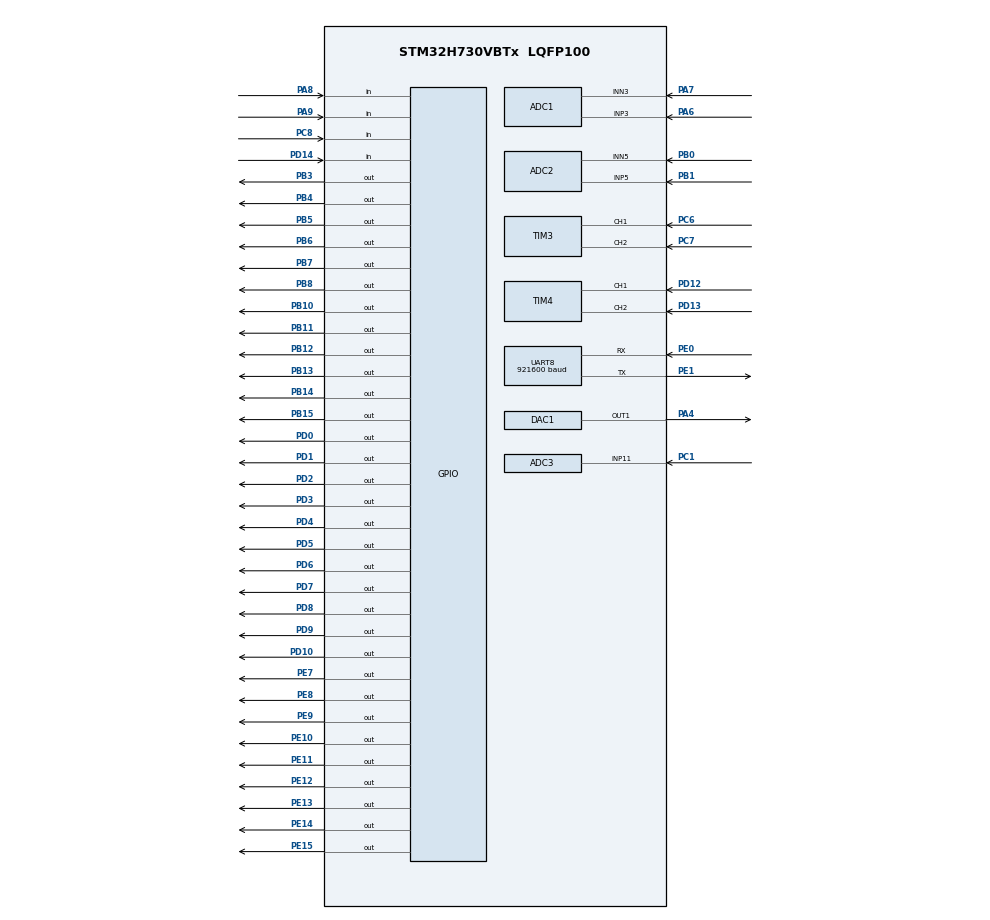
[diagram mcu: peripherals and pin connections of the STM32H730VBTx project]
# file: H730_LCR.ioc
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ADC1.Channel-1\#ChannelRegularConversion=ADC_CHANNEL_3
ADC1.ClockPrescaler=ADC_CLOCK_ASYNC_DIV1
ADC1.ClockPrescalerADC3=ADC_CLOCK_ASYNC_DIV16
ADC1.ContinuousConvMode=ENABLE
ADC1.ConversionDataManagement=ADC_CONVERSIONDATA_DR
ADC1.ExternalTrigConv=ADC_SOFTWARE_START
ADC1.Mode=ADC_DUALMODE_REGSIMULT
ADC1.NbrOfConversionFlag=1
ADC1.OffsetNumber-1\#ChannelRegularConversion=ADC_OFFSET_NONE
ADC1.OffsetSignedSaturation-1\#ChannelRegularConversion=DISABLE
ADC1.Overrun=ADC_OVR_DATA_OVERWRITTEN
ADC1.Rank-1\#ChannelRegularConversion=1
ADC1.SamplingTime-1\#ChannelRegularConversion=ADC_SAMPLETIME_8CYCLES_5
ADC1.SingleDiff-1\#ChannelRegularConversion=ADC_DIFFERENTIAL_ENDED
ADC1.master=1
ADC2.Channel-1\#ChannelRegularConversion=ADC_CHANNEL_5
ADC2.ClockPrescalerADC3=ADC_CLOCK_ASYNC_DIV16
ADC2.ContinuousConvMode=ENABLE
ADC2.ConversionDataManagement=ADC_CONVERSIONDATA_DR
ADC2.Mode=ADC_DUALMODE_REGSIMULT
ADC2.NbrOfConversionFlag=1
ADC2.OffsetNumber-1\#ChannelRegularConversion=ADC_OFFSET_NONE
ADC2.OffsetSignedSaturation-1\#ChannelRegularConversion=DISABLE
ADC2.Overrun=ADC_OVR_DATA_OVERWRITTEN
ADC2.Rank-1\#ChannelRegularConversion=1
ADC2.SamplingTime-1\#ChannelRegularConversion=ADC_SAMPLETIME_8CYCLES_5
ADC2.SingleDiff-1\#ChannelRegularConversion=ADC_DIFFERENTIAL_ENDED
ADC3.Channel-5\#ChannelRegularConversion=ADC_CHANNEL_11
ADC3.ClockPrescaler=ADC_CLOCK_ASYNC_DIV1
ADC3.ClockPrescalerADC3=ADC_CLOCK_ASYNC_DIV16
ADC3.Mode=ADC_DUALMODE_REGSIMULT
ADC3.NbrOfConversionFlag=1
ADC3.OffsetNumber-5\#ChannelRegularConversion=ADC_OFFSET_NONE
ADC3.OffsetSign-5\#ChannelRegularConversion=ADC3_OFFSET_SIGN_NEGATIVE
ADC3.OversamplingMode=ENABLE
ADC3.Rank-5\#ChannelRegularConversion=1
ADC3.Ratio=ADC3_OVERSAMPLING_RATIO_4
ADC3.SamplingTime-5\#ChannelRegularConversion=ADC3_SAMPLETIME_12CYCLES_5
CORTEX_M7.AccessPermission-Cortex_Memory_Protection_Unit_Region0_Settings=MPU_REGION_FULL_ACCESS
CORTEX_M7.BaseAddress-Cortex_Memory_Protection_Unit_Region0_Settings=0x24000000
CORTEX_M7.CPU_DCache=Enabled
CORTEX_M7.CPU_ICache=Enabled
CORTEX_M7.Enable-Cortex_Memory_Protection_Unit_Region0_Settings=MPU_REGION_ENABLE
CORTEX_M7.Enable-Cortex_Memory_Protection_Unit_Region1_Settings=__NULL
CORTEX_M7.IsShareable-Cortex_Memory_Protection_Unit_Region0_Settings=MPU_ACCESS_SHAREABLE
CORTEX_M7.MPU_Control=MPU_HFNMI_PRIVDEF
CORTEX_M7.Size-Cortex_Memory_Protection_Unit_Region0_Settings=MPU_REGION_SIZE_128KB
DAC1.DAC1_OutputBuffer-DAC_OUT1=DAC_OUTPUTBUFFER_DISABLE
DAC1.DAC_Channel-DAC_OUT1=DAC_CHANNEL_1
DAC1.DAC_Trigger-DAC_OUT1=DAC_TRIGGER_T7_TRGO
Dma.DAC1_CH1.0.Direction=DMA_MEMORY_TO_PERIPH
Dma.DAC1_CH1.0.EventEnable=DISABLE
Dma.DAC1_CH1.0.FIFOMode=DMA_FIFOMODE_DISABLE
Dma.DAC1_CH1.0.Instance=DMA1_Stream2
Dma.DAC1_CH1.0.MemDataAlignment=DMA_MDATAALIGN_HALFWORD
Dma.DAC1_CH1.0.MemInc=DMA_MINC_ENABLE
Dma.DAC1_CH1.0.Mode=DMA_CIRCULAR
Dma.DAC1_CH1.0.PeriphDataAlignment=DMA_PDATAALIGN_HALFWORD
Dma.DAC1_CH1.0.PeriphInc=DMA_PINC_DISABLE
Dma.DAC1_CH1.0.Polarity=HAL_DMAMUX_REQ_GEN_RISING
Dma.DAC1_CH1.0.Priority=DMA_PRIORITY_VERY_HIGH
Dma.DAC1_CH1.0.RequestNumber=1
Dma.DAC1_CH1.0.SignalID=NONE
Dma.DAC1_CH1.0.SyncEnable=DISABLE
Dma.DAC1_CH1.0.SyncPolarity=HAL_DMAMUX_SYNC_NO_EVENT
Dma.DAC1_CH1.0.SyncRequestNumber=1
Dma.DAC1_CH1.0.SyncSignalID=NONE
Dma.Request0=DAC1_CH1
Mcu.Family=STM32H7
Mcu.Name=STM32H730VBTx
Mcu.Package=LQFP100
NVIC.DMA1_Stream2_IRQn=true\:0\:0\:false\:false\:true\:false\:true\:true
NVIC.PriorityGroup=NVIC_PRIORITYGROUP_3
PA13(JTMS/SWDIO).Mode=Serial_Wire
PA13(JTMS/SWDIO).Signal=DEBUG_JTMS-SWDIO
PA14(JTCK/SWCLK).Mode=Serial_Wire
PA14(JTCK/SWCLK).Signal=DEBUG_JTCK-SWCLK
PA4.Signal=COMP_DAC11_group
PA6.Signal=ADCx_INP3
PA7.Signal=ADCx_INN3
PA8.GPIO_PuPd=GPIO_PULLUP
PA8.Signal=GPIO_Input
PA9.GPIO_PuPd=GPIO_PULLUP
PA9.Signal=GPIO_Input
PB0.Signal=ADCx_INN5
PB1.Signal=ADCx_INP5
PB10.Signal=GPIO_Output
PB11.Signal=GPIO_Output
PB12.Signal=GPIO_Output
PB13.Signal=GPIO_Output
PB14.Signal=GPIO_Output
PB15.Signal=GPIO_Output
PB3(JTDO/TRACESWO).Signal=GPIO_Output
PB4(NJTRST).Signal=GPIO_Output
PB5.Signal=GPIO_Output
PB6.Signal=GPIO_Output
PB7.Signal=GPIO_Output
PB8.Signal=GPIO_Output
PC1.Signal=ADCx_INP11
PC6.GPIO_PuPd=GPIO_NOPULL
PC6.Signal=S_TIM3_CH1
PC7.GPIO_PuPd=GPIO_NOPULL
PC7.Signal=S_TIM3_CH2
PC8.GPIO_PuPd=GPIO_PULLUP
PC8.Signal=GPIO_Input
PD0.Signal=GPIO_Output
PD1.Signal=GPIO_Output
PD10.Signal=GPIO_Output
PD12.Signal=S_TIM4_CH1
PD13.Signal=S_TIM4_CH2
PD14.GPIO_PuPd=GPIO_PULLUP
PD14.Signal=GPIO_Input
PD2.Signal=GPIO_Output
PD3.Signal=GPIO_Output
PD4.Signal=GPIO_Output
PD5.Signal=GPIO_Output
PD6.Signal=GPIO_Output
PD7.Signal=GPIO_Output
PD8.Signal=GPIO_Output
PD9.Signal=GPIO_Output
PE0.Mode=Asynchronous
PE0.Signal=UART8_RX
PE1.Mode=Asynchronous
PE1.Signal=UART8_TX
PE10.Signal=GPIO_Output
PE11.Signal=GPIO_Output
PE12.Signal=GPIO_Output
PE13.Signal=GPIO_Output
PE14.Signal=GPIO_Output
PE15.Signal=GPIO_Output
PE7.Signal=GPIO_Output
PE8.Signal=GPIO_Output
PE9.Signal=GPIO_Output
PH0-OSC_IN.Mode=HSE-External-Oscillator
PH0-OSC_IN.Signal=RCC_OSC_IN
PH1-OSC_OUT.Mode=HSE-External-Oscillator
PH1-OSC_OUT.Signal=RCC_OSC_OUT
ProjectManager.HeapSize=0x200
ProjectManager.StackSize=0x400
ProjectManager.TargetToolchain=Makefile
RCC.ADCFreq_Value=53040000
RCC.APB1Freq_Value=60000000
RCC.APB2Freq_Value=60000000
RCC.APB3Freq_Value=60000000
RCC.APB4Freq_Value=60000000
RCC.CortexFreq_Value=120000000
RCC.D1PPRE=RCC_APB3_DIV2
RCC.D2PPRE1=RCC_APB1_DIV2
RCC.D2PPRE2=RCC_APB2_DIV2
RCC.D3PPRE=RCC_APB4_DIV2
RCC.DIVM1=2
RCC.DIVM2=10
RCC.DIVM3=1
RCC.DIVN1=20
RCC.DIVN2=221
RCC.DIVN3=20
RCC.DIVP2=10
RCC.DIVQ1=20
RCC.DIVQ3=6
RCC.DIVR3=1
RCC.EnbaleCSS=false
RCC.HCLKFreq_Value=120000000
RCC.HSE_VALUE=24000000
RCC.HSIDiv=RCC_PLLSAIDIVR_2
RCC.PLL2_VCI_Range-AdvancedSettings=RCC_PLL2VCIRANGE_1
RCC.PLL2_VCO_SEL-AdvancedSettings=RCC_PLL2VCOMEDIUM
RCC.PLLSourceVirtual=RCC_PLLSOURCE_HSE
RCC.PWR_Regulator_Voltage_Scale=PWR_REGULATOR_VOLTAGE_SCALE2
RCC.RCC_MCO1Source=RCC_MCO1SOURCE_HSE
RCC.RNGCLockSelection=RCC_RNGCLKSOURCE_PLL
RCC.SYSCLKFreq_VALUE=120000000
RCC.SYSCLKSource=RCC_SYSCLKSOURCE_PLLCLK
RCC.USBCLockSelection=RCC_USBCLKSOURCE_PLL3
RCC.USBFreq_Value=80000000
SH.ADCx_INN3.0=ADC1_INN3,IN3-Differential
SH.ADCx_INN5.0=ADC2_INN5,IN5-Differential
SH.ADCx_INP11.0=ADC3_INP11,IN11-Single-Ended
SH.ADCx_INP3.0=ADC1_INP3,IN3-Differential
SH.ADCx_INP5.0=ADC2_INP5,IN5-Differential
SH.COMP_DAC11_group.0=DAC1_OUT1,DAC_OUT1
SH.S_TIM3_CH1.0=TIM3_CH1,Encoder_Interface
SH.S_TIM3_CH2.0=TIM3_CH2,Encoder_Interface
SH.S_TIM4_CH1.0=TIM4_CH1,Encoder_Interface
SH.S_TIM4_CH2.0=TIM4_CH2,Encoder_Interface
TIM3.CounterMode=TIM_COUNTERMODE_UP
TIM3.EncoderMode=TIM_ENCODERMODE_TI12
TIM3.IC1Polarity=TIM_ICPOLARITY_FALLING
TIM3.IC2Polarity=TIM_ICPOLARITY_RISING
TIM4.CounterMode=TIM_COUNTERMODE_UP
TIM4.EncoderMode=TIM_ENCODERMODE_TI12
TIM4.IC1Polarity=TIM_ICPOLARITY_FALLING
TIM4.IC2Polarity=TIM_ICPOLARITY_RISING
TIM7.Period=65535
TIM7.TIM_MasterOutputTrigger=TIM_TRGO_UPDATE
UART8.BaudRate=921600
VP_MEMORYMAP_VS_MEMORYMAP.Mode=CurAppReg
VP_RNG_VS_RNG.Mode=RNG_Activate
VP_TIM23_VS_ClockSourceINT.Mode=Internal
VP_TIM7_VS_ClockSourceINT.Mode=Enable_Timer
board=custom

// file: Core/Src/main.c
/* USER CODE BEGIN Header */
/**
 ******************************************************************************
 * @file           : main.c
 * @brief          : Main program body
 ******************************************************************************
 * @attention
 *
 * Copyright (c) 2024 STMicroelectronics.
 * All rights reserved.
 *
 * This software is licensed under terms that can be found in the LICENSE file
 * in the root directory of this software component.
 * If no LICENSE file comes with this software, it is provided AS-IS.
 *
 ******************************************************************************
 */
/* USER CODE END Header */
#include "main.h"
#include "adc.h"
#include "dac.h"
#include "dma.h"
#include "rng.h"
#include "tim.h"
#include "usart.h"
#include "gpio.h"

/* USER CODE BEGIN Includes */
#include "main_cycle.hpp"
/* USER CODE END Includes */

void SystemClock_Config(void);
void PeriphCommonClock_Config(void);
static void MPU_Config(void);

int main(void)
{

    /* MPU Configuration--------------------------------------------------------*/
    MPU_Config();

    /* Enable the CPU Cache */

    /* Enable I-Cache---------------------------------------------------------*/
    SCB_EnableICache();

    /* Enable D-Cache---------------------------------------------------------*/
    SCB_EnableDCache();

    /* MCU Configuration--------------------------------------------------------*/

    /* Reset of all peripherals, Initializes the Flash interface and the Systick. */
    HAL_Init();

    /* USER CODE BEGIN Init */
    // Reset analog peripherals
    __HAL_RCC_ADC12_FORCE_RESET();
    __HAL_RCC_ADC12_RELEASE_RESET();
    __HAL_RCC_DAC12_FORCE_RESET();
    __HAL_RCC_DAC12_RELEASE_RESET();
    /* USER CODE END Init */

    /* Configure the system clock */
    SystemClock_Config();

    /* Configure the peripherals common clocks */
    PeriphCommonClock_Config();

    /* Initialize all configured peripherals */
    MX_GPIO_Init();
    MX_DMA_Init();
    MX_ADC2_Init();
    MX_DAC1_Init();
    MX_ADC3_Init();
    MX_TIM3_Init();
    MX_TIM4_Init();
    MX_ADC1_Init();
    MX_UART8_Init();
    MX_TIM7_Init();
    MX_RNG_Init();
    MX_TIM23_Init();

    /* Infinite loop */
    /* USER CODE BEGIN WHILE */
    main_loop();
    while (1) {
        /* USER CODE END WHILE */

    }
}

void SystemClock_Config(void)
{
    RCC_OscInitTypeDef RCC_OscInitStruct = {0};
    RCC_ClkInitTypeDef RCC_ClkInitStruct = {0};

    /** Supply configuration update enable
     */
    HAL_PWREx_ConfigSupply(PWR_LDO_SUPPLY);

    /** Configure the main internal regulator output voltage
     */
    __HAL_PWR_VOLTAGESCALING_CONFIG(PWR_REGULATOR_VOLTAGE_SCALE2);

    while (!__HAL_PWR_GET_FLAG(PWR_FLAG_VOSRDY)) {
    }

    /** Initializes the RCC Oscillators according to the specified parameters
     * in the RCC_OscInitTypeDef structure.
     */
    RCC_OscInitStruct.OscillatorType = RCC_OSCILLATORTYPE_HSE;
    RCC_OscInitStruct.HSEState = RCC_HSE_ON;
    RCC_OscInitStruct.PLL.PLLState = RCC_PLL_ON;
    RCC_OscInitStruct.PLL.PLLSource = RCC_PLLSOURCE_HSE;
    RCC_OscInitStruct.PLL.PLLM = 2;
    RCC_OscInitStruct.PLL.PLLN = 20;
    RCC_OscInitStruct.PLL.PLLP = 2;
    RCC_OscInitStruct.PLL.PLLQ = 20;
    RCC_OscInitStruct.PLL.PLLR = 2;
    RCC_OscInitStruct.PLL.PLLRGE = RCC_PLL1VCIRANGE_3;
    RCC_OscInitStruct.PLL.PLLVCOSEL = RCC_PLL1VCOWIDE;
    RCC_OscInitStruct.PLL.PLLFRACN = 0;
    if (HAL_RCC_OscConfig(&RCC_OscInitStruct) != HAL_OK) {
        Error_Handler();
    }

    /** Initializes the CPU, AHB and APB buses clocks
     */
    RCC_ClkInitStruct.ClockType = RCC_CLOCKTYPE_HCLK | RCC_CLOCKTYPE_SYSCLK
                                  | RCC_CLOCKTYPE_PCLK1 | RCC_CLOCKTYPE_PCLK2
                                  | RCC_CLOCKTYPE_D3PCLK1 | RCC_CLOCKTYPE_D1PCLK1;
    RCC_ClkInitStruct.SYSCLKSource = RCC_SYSCLKSOURCE_PLLCLK;
    RCC_ClkInitStruct.SYSCLKDivider = RCC_SYSCLK_DIV1;
    RCC_ClkInitStruct.AHBCLKDivider = RCC_HCLK_DIV1;
    RCC_ClkInitStruct.APB3CLKDivider = RCC_APB3_DIV2;
    RCC_ClkInitStruct.APB1CLKDivider = RCC_APB1_DIV2;
    RCC_ClkInitStruct.APB2CLKDivider = RCC_APB2_DIV2;
    RCC_ClkInitStruct.APB4CLKDivider = RCC_APB4_DIV2;

    if (HAL_RCC_ClockConfig(&RCC_ClkInitStruct, FLASH_LATENCY_2) != HAL_OK) {
        Error_Handler();
    }
}

void PeriphCommonClock_Config(void)
{
    RCC_PeriphCLKInitTypeDef PeriphClkInitStruct = {0};

    /** Initializes the peripherals clock
     */
    PeriphClkInitStruct.PeriphClockSelection = RCC_PERIPHCLK_ADC;
    PeriphClkInitStruct.PLL2.PLL2M = 10;
    PeriphClkInitStruct.PLL2.PLL2N = 221;
    PeriphClkInitStruct.PLL2.PLL2P = 10;
    PeriphClkInitStruct.PLL2.PLL2Q = 2;
    PeriphClkInitStruct.PLL2.PLL2R = 2;
    PeriphClkInitStruct.PLL2.PLL2RGE = RCC_PLL2VCIRANGE_1;
    PeriphClkInitStruct.PLL2.PLL2VCOSEL = RCC_PLL2VCOWIDE;
    PeriphClkInitStruct.PLL2.PLL2FRACN = 0;
    PeriphClkInitStruct.AdcClockSelection = RCC_ADCCLKSOURCE_PLL2;
    if (HAL_RCCEx_PeriphCLKConfig(&PeriphClkInitStruct) != HAL_OK) {
        Error_Handler();
    }
}

/* MPU Configuration */

void MPU_Config(void)
{
    MPU_Region_InitTypeDef MPU_InitStruct = {0};

    /* Disables the MPU */
    HAL_MPU_Disable();

    /** Initializes and configures the Region and the memory to be protected
     */
    MPU_InitStruct.Enable = MPU_REGION_ENABLE;
    MPU_InitStruct.Number = MPU_REGION_NUMBER0;
    MPU_InitStruct.BaseAddress = 0x24000000;
    MPU_InitStruct.Size = MPU_REGION_SIZE_128KB;
    MPU_InitStruct.SubRegionDisable = 0x0;
    MPU_InitStruct.TypeExtField = MPU_TEX_LEVEL0;
    MPU_InitStruct.AccessPermission = MPU_REGION_FULL_ACCESS;
    MPU_InitStruct.DisableExec = MPU_INSTRUCTION_ACCESS_ENABLE;
    MPU_InitStruct.IsShareable = MPU_ACCESS_SHAREABLE;
    MPU_InitStruct.IsCacheable = MPU_ACCESS_NOT_CACHEABLE;
    MPU_InitStruct.IsBufferable = MPU_ACCESS_NOT_BUFFERABLE;

    HAL_MPU_ConfigRegion(&MPU_InitStruct);
    /* Enables the MPU */
    HAL_MPU_Enable(MPU_HFNMI_PRIVDEF);
}

void Error_Handler(void)
{
    __disable_irq();
    while (1) {
    }
}
